# MSS_GPADC_REG register map
Vendor: Texas Instruments
Peripheral module from a debugger description file (folder awr2544).
Registers are 32-bit, read-write, no defined reset value unless marked. A register's access mark holds for its fields unless they carry their own. Offsets are as the file gives them; lines under a group give offsets from that group; [hi:lo] are bit positions; {n}, {i} and the like mark numbered series; 'fields as' and 'values as' point back to an identical list; <NAME> marks a mode.

## MSS_GPADC_REG
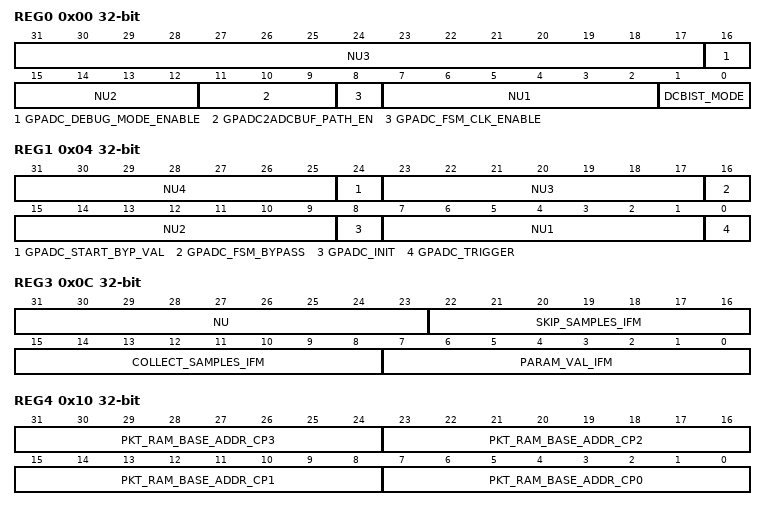
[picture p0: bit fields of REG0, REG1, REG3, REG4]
0x00 REG0 access per field — gpadc modes and enable
  [31:17] NU3 ro — TI reserved
  [16] GPADC_DEBUG_MODE_ENABLE rw — 1:GPADC raw samples will be collected in the Output RAM in IFM mode
  [15:12] NU2 ro — TI reserved
  [11:9] GPADC2ADCBUF_PATH_EN rw — TI reserved
  [8] GPADC_FSM_CLK_ENABLE rw — Enable the clock to gpadc fsm
  [7:2] NU1 ro — TI reserved
  [1:0] DCBIST_MODE rw — 0:Disable,1:IFM Mode enable ,2:CTM mode enable
0x04 REG1 access not given — gpadc start trigger for Inter frame mode
  [8n-1:8n-7] NU{n} ro (n=1..4) — TI reserved
  [24] GPADC_START_BYP_VAL rw
  [16] GPADC_FSM_BYPASS rw — 1:Bypass gpadc control .When bypassed start = gpadc_start_byp_val config_val = config_value_ifm param_val = param_val_ifm
  [8] GPADC_INIT — Resets the FSM and clears the data RAM
  [0] GPADC_TRIGGER — Generates a single cycle pulse to trigger the IFM mode
0x08 REG2 — gpadc config for IFM
  [31:0] CONFIG_VALUE_IFM — Configuration value to be passed to analog in IFM mode
0x0C REG3 access per field — gpadc param, skip samples and collect samples for IFM
  [31:23] NU ro
  [22:16] SKIP_SAMPLES_IFM rw — number of GPADC clocks to skip after trigger . Number of samples to skip = skip_samples_ifm[3:0]x(2skip_samples_ifm[6:4])
  [15:8] COLLECT_SAMPLES_IFM rw — number of GPADC readings to collect
  [7:0] PARAM_VAL_IFM rw — Param value to be passed to analog in IFM mode(after one hot encoding)
0x10 REG4 — Base address for Chirp profile 0 in instruction packet RAM
  [31:24] PKT_RAM_BASE_ADDR_CP3 — TI reserved
  [23:16] PKT_RAM_BASE_ADDR_CP2 — TI reserved
  [15:8] PKT_RAM_BASE_ADDR_CP1 — (End-Address + 1) of instruction-ram in CTM mode
  [7:0] PKT_RAM_BASE_ADDR_CP0 — Start Address of instruction-ram in CTM mode
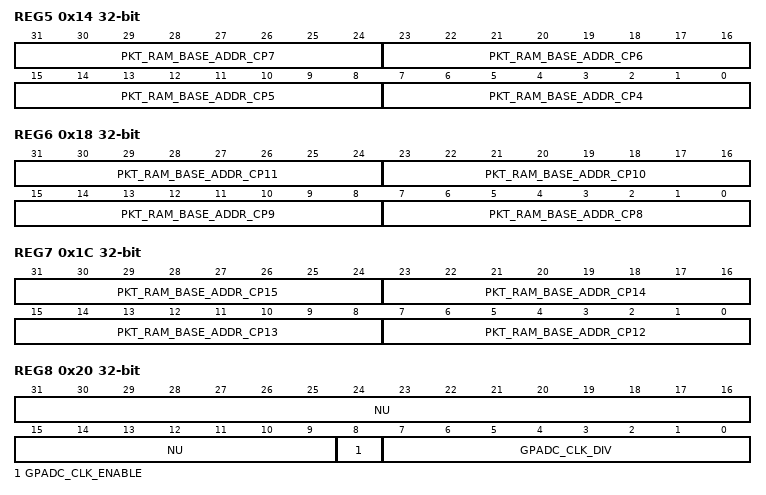
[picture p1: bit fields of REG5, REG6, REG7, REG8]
0x14 REG5 — Base address for Chirp profile 1 in instruction packet RAM
  [8n-25:8n-32] PKT_RAM_BASE_ADDR_CP{n} (n=4..7) — TI reserved
0x18 REG6 — Base address for Chirp profile 2 in instruction packet RAM
  [8n-57:8n-64] PKT_RAM_BASE_ADDR_CP{n} (n=8..11) — TI reserved
0x1C REG7 — Base address for Chirp profile 3 in instruction packet RAM
  [8n-89:8n-96] PKT_RAM_BASE_ADDR_CP{n} (n=12..15) — TI reserved
0x20 REG8 access per field
  [31:9] NU ro
  [8] GPADC_CLK_ENABLE rw — TI reserved
  [7:0] GPADC_CLK_DIV rw — TI reserved
{0x0+4i} REG{i} (i=9..11)
  [31:0] PARAM_NOT_USED_TX_ENA{i-8}_OFF — TI reserved
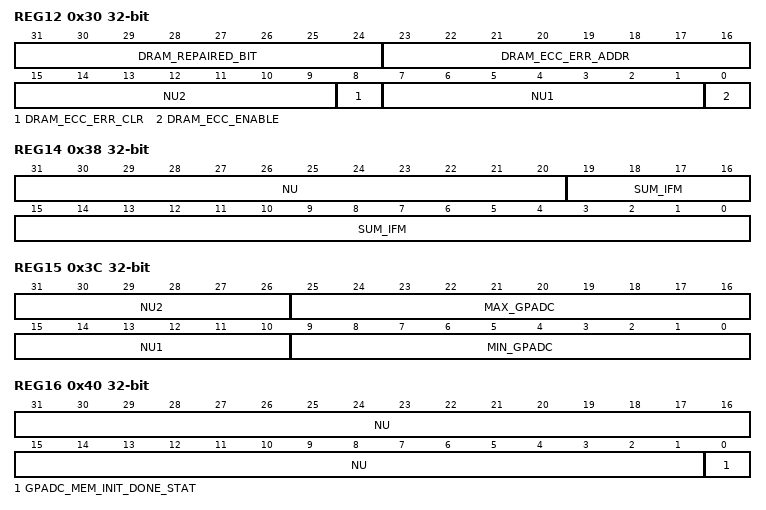
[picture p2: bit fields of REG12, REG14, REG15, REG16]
0x30 REG12 access not given
  [31:24] DRAM_REPAIRED_BIT ro — TI reserved
  [23:16] DRAM_ECC_ERR_ADDR ro — TI reserved
  [15:9] NU2 ro — TI reserved
  [8] DRAM_ECC_ERR_CLR — TI reserved
  [7:1] NU1 ro — TI reserved
  [0] DRAM_ECC_ENABLE rw
0x34 REG13
  [31:0] SPARE_WR2 — TI reserved
0x38 REG14 ro — Sum of GP ADC readings
  [31:20] NU — TI reserved
  [19:0] SUM_IFM — Sum of GP ADC readings
0x3C REG15 ro — Min and Max of GP ADC readings
  [31:26] NU2 — TI reserved
  [25:16] MAX_GPADC — Max of GPADC readings
  [15:10] NU1 — TI reserved
  [9:0] MIN_GPADC — Min of GPADC readings
0x40 REG16 ro
  [31:1] NU — TI reserved
  [0] GPADC_MEM_INIT_DONE_STAT — Status for Data Mem init done.Used for FW polling .Will read '0' when init process is under progress
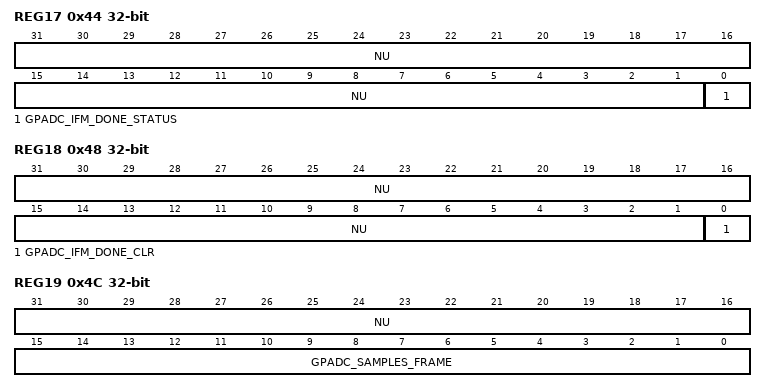
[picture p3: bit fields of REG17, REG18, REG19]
0x44 REG17 ro
  [31:1] NU — TI reserved
  [0] GPADC_IFM_DONE_STATUS — Test completion status in IFM mode.Used for FW polling
0x48 REG18 access not given
  [31:1] NU ro — TI reserved
  [0] GPADC_IFM_DONE_CLR — Clear "ifm_done_status"
0x4C REG19 ro
  [31:16] NU — TI reserved
  [15:0] GPADC_SAMPLES_FRAME — Total number of GPADC samples collected in a frame
0x50 REG20 ro
  [31:0] SPARE_RD1 — TI reserved
0x54 REG21 ro
  [31:0] SPARE_RD2 — TI reserved
0x58 REG22
  [31:0] SPARE_WR1 — TI reserved
